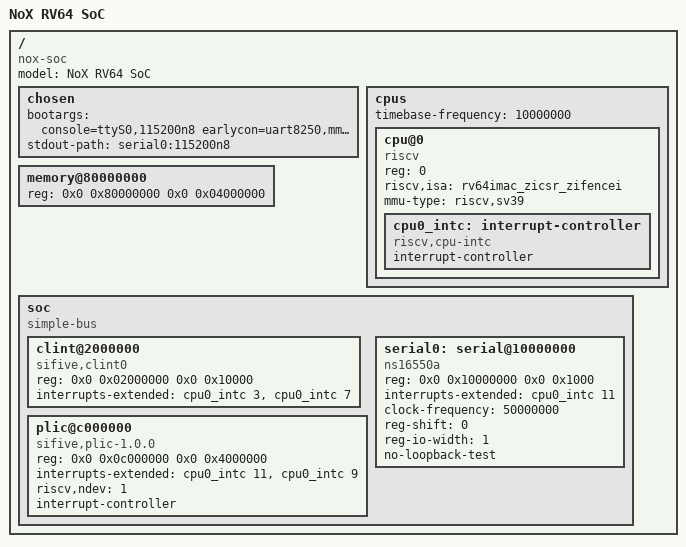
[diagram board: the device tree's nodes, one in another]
/dts-v1/;

/ {
	#address-cells = <2>;
	#size-cells = <2>;
	compatible = "nox-soc";
	model = "NoX RV64 SoC";

	chosen {
		bootargs = "console=ttyS0,115200n8 earlycon=uart8250,mmio8,0x10000000,115200n8 rootfstype=ramfs init=/init";
		stdout-path = "serial0:115200n8";
	};

	cpus {
		#address-cells = <1>;
		#size-cells = <0>;
		timebase-frequency = <10000000>;  /* 10 MHz — matches CLINT mtime increment */

		cpu@0 {
			device_type = "cpu";
			reg = <0>;
			compatible = "riscv";
			riscv,isa = "rv64imac_zicsr_zifencei";
			mmu-type = "riscv,sv39";
			status = "okay";

			cpu0_intc: interrupt-controller {
				#interrupt-cells = <1>;
				compatible = "riscv,cpu-intc";
				interrupt-controller;
			};
		};
	};

	memory@80000000 {
		device_type = "memory";
		reg = <0x0 0x80000000 0x0 0x04000000>;  /* 64 MB */
	};

	soc {
		#address-cells = <2>;
		#size-cells = <2>;
		compatible = "simple-bus";
		ranges;

		clint@2000000 {
			compatible = "sifive,clint0", "riscv,clint0";
			reg = <0x0 0x02000000 0x0 0x10000>;
			interrupts-extended = <&cpu0_intc 3>,   /* MSI */
			                      <&cpu0_intc 7>;   /* MTI */
		};

		plic@c000000 {
			compatible = "sifive,plic-1.0.0", "riscv,plic0";
			reg = <0x0 0x0c000000 0x0 0x4000000>;
			interrupts-extended = <&cpu0_intc 11>,  /* MEI */
			                      <&cpu0_intc 9>;   /* SEI */
			riscv,ndev = <1>;
			#interrupt-cells = <1>;
			#address-cells = <0>;
			interrupt-controller;
		};

		serial0: serial@10000000 {
			compatible = "ns16550a";
			reg = <0x0 0x10000000 0x0 0x1000>;
			interrupts-extended = <&cpu0_intc 11>;
			clock-frequency = <50000000>;
			reg-shift = <0>;
			reg-io-width = <1>;
			no-loopback-test;
		};
	};
};
